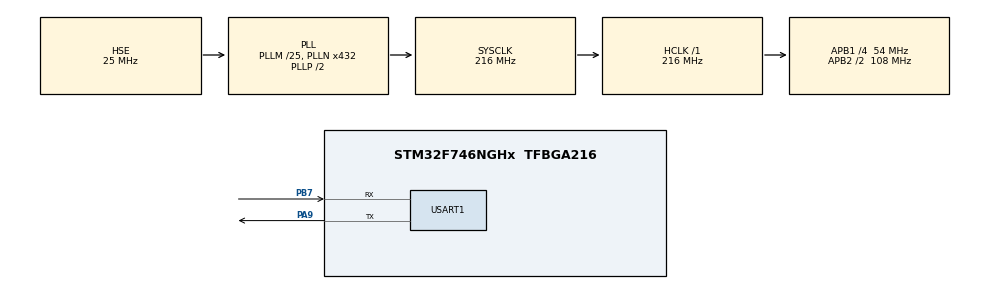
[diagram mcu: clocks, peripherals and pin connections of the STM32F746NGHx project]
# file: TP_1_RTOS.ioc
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FREERTOS.Tasks01=defaultTask,0,128,StartDefaultTask,Default,NULL,Dynamic,NULL,NULL
Mcu.Family=STM32F7
Mcu.Name=STM32F746NGHx
Mcu.Package=TFBGA216
NVIC.PriorityGroup=NVIC_PRIORITYGROUP_4
NVIC.TIM6_DAC_IRQn=true\:15\:0\:false\:false\:true\:false\:false\:true
NVIC.TimeBase=TIM6_DAC_IRQn
NVIC.TimeBaseIP=TIM6
PA13.Mode=Serial_Wire
PA13.Signal=SYS_JTMS-SWDIO
PA14.Mode=Serial_Wire
PA14.Signal=SYS_JTCK-SWCLK
PA9.Mode=Asynchronous
PA9.Signal=USART1_TX
PB7.Mode=Asynchronous
PB7.Signal=USART1_RX
PH0/OSC_IN.Mode=HSE-External-Oscillator
PH0/OSC_IN.Signal=RCC_OSC_IN
PH1/OSC_OUT.Mode=HSE-External-Oscillator
PH1/OSC_OUT.Signal=RCC_OSC_OUT
ProjectManager.HeapSize=0x200
ProjectManager.StackSize=0x400
ProjectManager.TargetToolchain=STM32CubeIDE
RCC.AHBFreq_Value=216000000
RCC.APB1CLKDivider=RCC_HCLK_DIV4
RCC.APB1Freq_Value=54000000
RCC.APB1TimFreq_Value=108000000
RCC.APB2CLKDivider=RCC_HCLK_DIV2
RCC.APB2Freq_Value=108000000
RCC.APB2TimFreq_Value=216000000
RCC.CortexFreq_Value=216000000
RCC.HCLKFreq_Value=216000000
RCC.HSE_VALUE=25000000
RCC.HSI_VALUE=16000000
RCC.LSE_VALUE=32768
RCC.PLLM=25
RCC.PLLN=432
RCC.PLLSourceVirtual=RCC_PLLSOURCE_HSE
RCC.SYSCLKFreq_VALUE=216000000
RCC.SYSCLKSource=RCC_SYSCLKSOURCE_PLLCLK
RCC.USBFreq_Value=216000000
RCC.VCOOutputFreq_Value=432000000
USART1.VirtualMode-Asynchronous=VM_ASYNC
VP_FREERTOS_VS_CMSIS_V1.Mode=CMSIS_V1
VP_SYS_VS_tim6.Mode=TIM6
board=STM32F746G-DISCO

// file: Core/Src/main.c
/* USER CODE BEGIN Header */
/**
 ******************************************************************************
 * @file           : main.c
 * @brief          : Main program body
 ******************************************************************************
 * @attention
 *
 * <h2><center>&copy; Copyright (c) 2021 STMicroelectronics.
 * All rights reserved.</center></h2>
 *
 * This software component is licensed by ST under BSD 3-Clause license,
 * the "License"; You may not use this file except in compliance with the
 * License. You may obtain a copy of the License at:
 *                        opensource.org/licenses/BSD-3-Clause
 *
 ******************************************************************************
 */
/* USER CODE END Header */
#include "main.h"
#include "cmsis_os.h"
#include "usart.h"
#include "gpio.h"

/* USER CODE BEGIN Includes */
#include <stdio.h>
/* USER CODE END Includes */

void SystemClock_Config(void);
void MX_FREERTOS_Init(void);

/* USER CODE BEGIN 0 */
int __io_putchar(int ch) {
	HAL_UART_Transmit(&huart1, (uint8_t *)&ch, 1, HAL_MAX_DELAY);
	return ch;
}
/* USER CODE END 0 */

int main(void)
{

  /* MCU Configuration--------------------------------------------------------*/

  /* Reset of all peripherals, Initializes the Flash interface and the Systick. */
  HAL_Init();

  /* Configure the system clock */
  SystemClock_Config();

  /* Initialize all configured peripherals */
  MX_GPIO_Init();
  MX_USART1_UART_Init();
  /* USER CODE BEGIN 2 */
  printf("Launching program RTOS Lab\r\n"); //Launching message
  /*
   * Creation of the task defined in the tasks.c file
   */
  TaskHandle_t xHandle=NULL;	//Handler of task
  xTaskCreate(vTask_Test_Sleep, "Sleep", 1000, (uint8_t *)1,1, &xHandle); //Creation of the task working alone

  TaskHandle_t xHandle_Call=NULL;
  xTaskCreate(vTask_ToCall, "Call", 1000, (uint8_t *)1,2, &xHandle_Call);

  TaskHandle_t xHandle_Sync=NULL;
  xTaskCreate(vTask_Synchronising, "Synchro", 1000, (uint8_t *)1,3, &xHandle_Sync);
  /* USER CODE END 2 */

  /* Call init function for freertos objects (in freertos.c) */
  MX_FREERTOS_Init();
  /* Start scheduler */
  osKernelStart();

  /* We should never get here as control is now taken by the scheduler */
  /* Infinite loop */
	while (1)
	{

	}
}

void SystemClock_Config(void)
{
  RCC_OscInitTypeDef RCC_OscInitStruct = {0};
  RCC_ClkInitTypeDef RCC_ClkInitStruct = {0};
  RCC_PeriphCLKInitTypeDef PeriphClkInitStruct = {0};

  /** Configure the main internal regulator output voltage
  */
  __HAL_RCC_PWR_CLK_ENABLE();
  __HAL_PWR_VOLTAGESCALING_CONFIG(PWR_REGULATOR_VOLTAGE_SCALE1);
  /** Initializes the RCC Oscillators according to the specified parameters
  * in the RCC_OscInitTypeDef structure.
  */
  RCC_OscInitStruct.OscillatorType = RCC_OSCILLATORTYPE_HSE;
  RCC_OscInitStruct.HSEState = RCC_HSE_ON;
  RCC_OscInitStruct.PLL.PLLState = RCC_PLL_ON;
  RCC_OscInitStruct.PLL.PLLSource = RCC_PLLSOURCE_HSE;
  RCC_OscInitStruct.PLL.PLLM = 25;
  RCC_OscInitStruct.PLL.PLLN = 432;
  RCC_OscInitStruct.PLL.PLLP = RCC_PLLP_DIV2;
  RCC_OscInitStruct.PLL.PLLQ = 2;
  if (HAL_RCC_OscConfig(&RCC_OscInitStruct) != HAL_OK)
  {
    Error_Handler();
  }
  /** Activate the Over-Drive mode
  */
  if (HAL_PWREx_EnableOverDrive() != HAL_OK)
  {
    Error_Handler();
  }
  /** Initializes the CPU, AHB and APB buses clocks
  */
  RCC_ClkInitStruct.ClockType = RCC_CLOCKTYPE_HCLK|RCC_CLOCKTYPE_SYSCLK
                              |RCC_CLOCKTYPE_PCLK1|RCC_CLOCKTYPE_PCLK2;
  RCC_ClkInitStruct.SYSCLKSource = RCC_SYSCLKSOURCE_PLLCLK;
  RCC_ClkInitStruct.AHBCLKDivider = RCC_SYSCLK_DIV1;
  RCC_ClkInitStruct.APB1CLKDivider = RCC_HCLK_DIV4;
  RCC_ClkInitStruct.APB2CLKDivider = RCC_HCLK_DIV2;

  if (HAL_RCC_ClockConfig(&RCC_ClkInitStruct, FLASH_LATENCY_7) != HAL_OK)
  {
    Error_Handler();
  }
  PeriphClkInitStruct.PeriphClockSelection = RCC_PERIPHCLK_USART1;
  PeriphClkInitStruct.Usart1ClockSelection = RCC_USART1CLKSOURCE_PCLK2;
  if (HAL_RCCEx_PeriphCLKConfig(&PeriphClkInitStruct) != HAL_OK)
  {
    Error_Handler();
  }
}

void HAL_TIM_PeriodElapsedCallback(TIM_HandleTypeDef *htim)
{
  if (htim->Instance == TIM6) {
    HAL_IncTick();
  }
}

void Error_Handler(void)
{
	__disable_irq();
	while (1)
	{
	}
}

/************************ (C) COPYRIGHT STMicroelectronics *****END OF FILE****/
